# HC32K118 register map
File version: 1.0
CPU: CM0+ r0p1, little endian, no MPU, no FPU, 2 interrupt priority bits
Registers are 32-bit, read-write, reset 0x0 unless marked. A register's access mark holds for its fields unless they carry their own. Offsets are from the block's base; [hi:lo] are bit positions; {n}, {i} and the like mark numbered series; 'fields as' and 'values as' point back to an identical list.

## DMA
Base 0x40013000
0x00 EN
  [0] EN
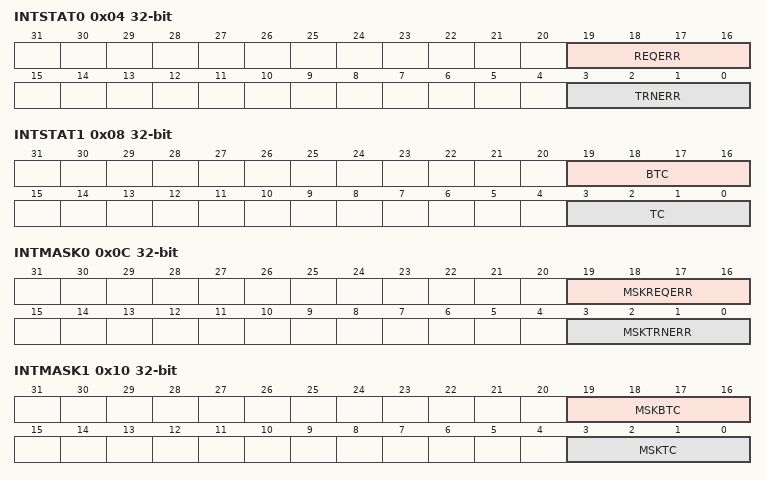
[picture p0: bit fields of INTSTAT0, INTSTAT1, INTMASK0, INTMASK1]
0x04 INTSTAT0 ro
  [19:16] REQERR, [3:0] TRNERR
0x08 INTSTAT1 ro
  [19:16] BTC, [3:0] TC
0x0C INTMASK0
  [19:16] MSKREQERR, [3:0] MSKTRNERR
0x10 INTMASK1
  [19:16] MSKBTC, [3:0] MSKTC
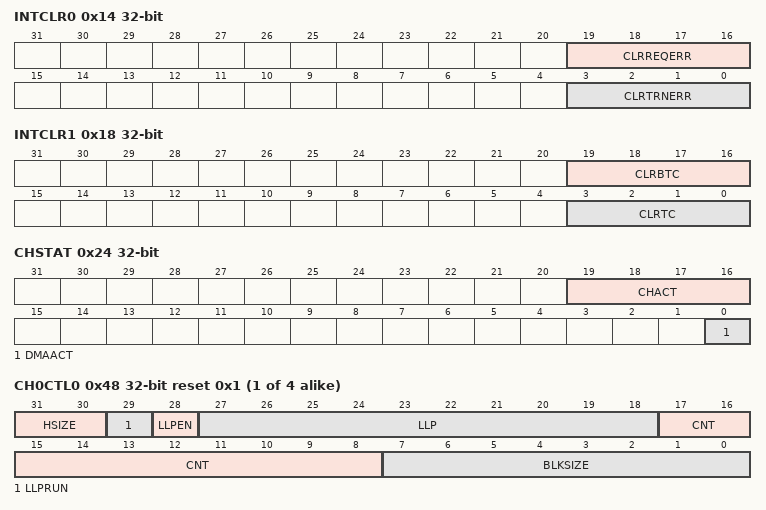
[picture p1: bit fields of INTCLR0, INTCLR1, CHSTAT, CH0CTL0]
0x14 INTCLR0 wo
  [19:16] CLRREQERR, [3:0] CLRTRNERR
0x18 INTCLR1 wo
  [19:16] CLRBTC, [3:0] CLRTC
0x1C CHEN
  [3:0] CHEN
0x24 CHSTAT ro
  [19:16] CHACT, [0] DMAACT
0x30 BASE1_LLP reset 0x20000000
  [31:14] LLP
0x34 BASE2_LLP
  [31:14] LLP
0x38 CHENCLR wo
  [3:0] CHENCLR
{0x40+0x40*i} SAR{i} (i=0..3)
{0x44+0x40*i} DAR{i} (i=0..3)
{0x48+0x40*i} CH{i}CTL0 reset 0x1 (i=0..3)
  [31:30] HSIZE, [29] LLPRUN, [28] LLPEN, [27:18] LLP, [17:8] CNT, [7:0] BLKSIZE
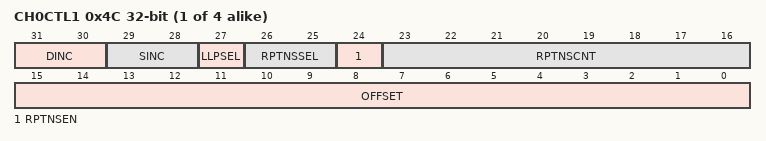
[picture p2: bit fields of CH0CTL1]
{0x4C+0x40*i} CH{i}CTL1 (i=0..3)
  [31:30] DINC, [29:28] SINC, [27] LLPSEL, [26:25] RPTNSSEL, [24] RPTNSEN, [23:16] RPTNSCNT, [15:0] OFFSET

## EFM
Base 0x40000400
0x00 DFAPRT
  [15:0] FAPRT
0x04 DKEY1
0x08 DKEY2
0x14 DFSTP
  [0] FSTP
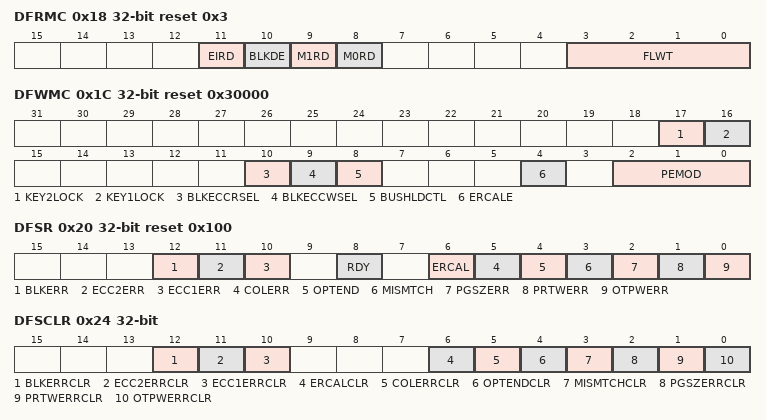
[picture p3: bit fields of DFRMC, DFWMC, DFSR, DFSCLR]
0x18 DFRMC reset 0x3
  [11] EIRD, [10] BLKDE, [9] M1RD, [8] M0RD, [3:0] FLWT
0x1C DFWMC reset 0x30000
  [17] KEY2LOCK, [16] KEY1LOCK, [10] BLKECCRSEL, [9] BLKECCWSEL, [8] BUSHLDCTL, [4] ERCALE, [2:0] PEMOD
0x20 DFSR ro reset 0x100
  [12] BLKERR, [11] ECC2ERR, [10] ECC1ERR, [8] RDY, [6] ERCAL, [5] COLERR, [4] OPTEND, [3] MISMTCH, [2] PGSZERR, [1] PRTWERR, [0] OTPWERR
0x24 DFSCLR
  [12] BLKERRCLR, [11] ECC2ERRCLR, [10] ECC1ERRCLR, [6] ERCALCLR, [5] COLERRCLR, [4] OPTENDCLR, [3] MISMTCHCLR, [2] PGSZERRCLR, [1] PRTWERRCLR, [0] OTPWERRCLR
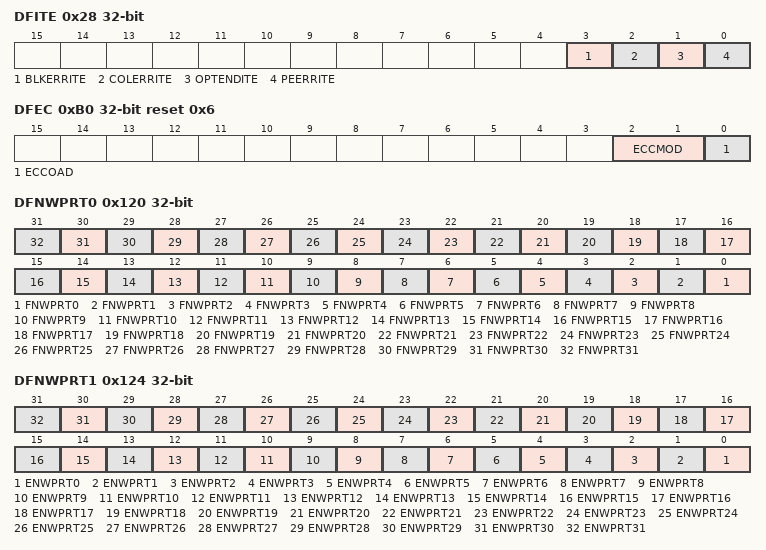
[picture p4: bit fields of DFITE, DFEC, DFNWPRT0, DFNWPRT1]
0x28 DFITE
  [3] BLKERRITE, [2] COLERRITE, [1] OPTENDITE, [0] PEERRITE
0xB0 DFEC reset 0x6
  [2:1] ECCMOD, [0] ECCOAD
0xB4 DFECERA ro reset 0x40000000
0xB8 DERI0
0xC0 DERI2
  [6:0] ERI2
0x120 DFNWPRT0
  [n] FNWPRT{n} (n=0..31)
0x124 DFNWPRT1
  [n] ENWPRT{n} (n=0..31)
0x400 FAPRT
  [15:0] FAPRT
0x404 KEY1
0x408 KEY2
0x414 FSTP
  [0] FSTP
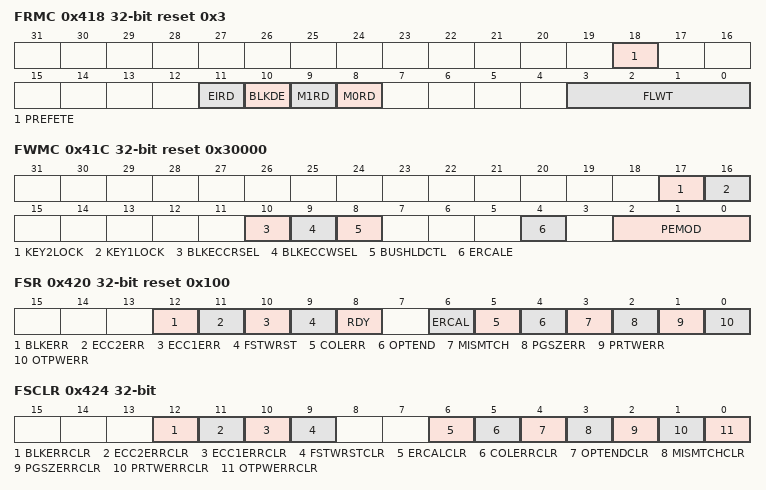
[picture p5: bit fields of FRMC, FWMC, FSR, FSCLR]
0x418 FRMC reset 0x3
  [18] PREFETE, [11] EIRD, [10] BLKDE, [9] M1RD, [8] M0RD, [3:0] FLWT
0x41C FWMC reset 0x30000
  fields as DFWMC
0x420 FSR ro reset 0x100
  [12] BLKERR, [11] ECC2ERR, [10] ECC1ERR, [9] FSTWRST, [8] RDY, [6] ERCAL, [5] COLERR, [4] OPTEND, [3] MISMTCH, [2] PGSZERR, [1] PRTWERR, [0] OTPWERR
0x424 FSCLR
  [12] BLKERRCLR, [11] ECC2ERRCLR, [10] ECC1ERRCLR, [9] FSTWRSTCLR, [6] ERCALCLR, [5] COLERRCLR, [4] OPTENDCLR, [3] MISMTCHCLR, [2] PGSZERRCLR, [1] PRTWERRCLR, [0] OTPWERRCLR
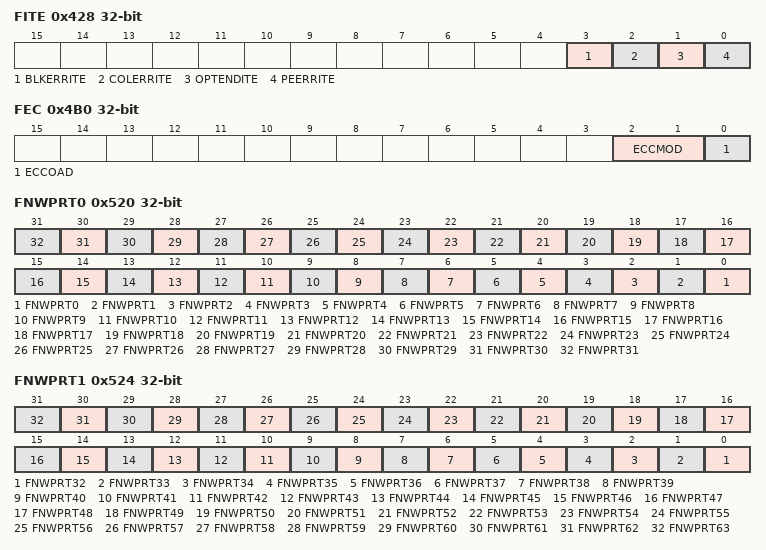
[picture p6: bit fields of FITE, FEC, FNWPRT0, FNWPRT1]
0x428 FITE
  [3] BLKERRITE, [2] COLERRITE, [1] OPTENDITE, [0] PEERRITE
0x42C FSWP ro
  [0] FSWP
0x440 CHIPID ro reset 0x58480118
{0x450+4i} UQID{i} ro (i=0..2)
0x4B0 FEC
  [2:1] ECCMOD, [0] ECCOAD
0x4B4 FECERA ro
0x4B8 ERI0
0x4BC ERI1
0x4C0 ERI2
  [7:0] ERI2
0x520 FNWPRT0
  [n] FNWPRT{n} (n=0..31)
0x524 FNWPRT1
  [n-32] FNWPRT{n} (n=32..63)
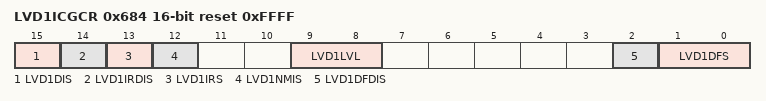
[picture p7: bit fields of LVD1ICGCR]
0x684 LVD1ICGCR 16-bit ro reset 0xFFFF
  [15] LVD1DIS, [14] LVD1IRDIS, [13] LVD1IRS, [12] LVD1NMIS, [9:8] LVD1LVL, [2] LVD1DFDIS, [1:0] LVD1DFS
0x686 HRCCFGR 8-bit
  [3:0] HRCFREQS

## EMB
Base 0x40006C00
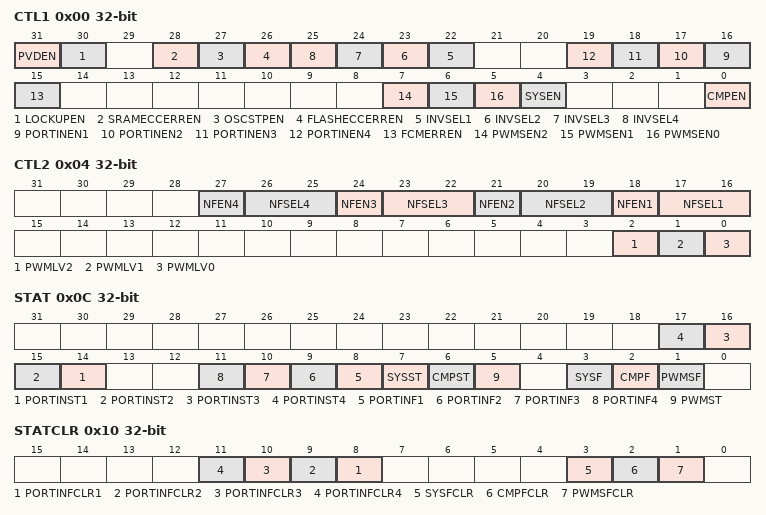
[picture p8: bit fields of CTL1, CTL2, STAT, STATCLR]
0x00 CTL1
  [31] PVDEN, [30] LOCKUPEN, [28] SRAMECCERREN, [27] OSCSTPEN, [26] FLASHECCERREN, [n+21] INVSEL{n} (n=1..4), [n+15] PORTINEN{n} (n=1..4), [15] FCMERREN, [7] PWMSEN2, [6] PWMSEN1, [5] PWMSEN0, [4] SYSEN, [0] CMPEN
0x04 CTL2
  [3n+15] NFEN{n} (n=1..4), [3n+14:3n+13] NFSEL{n} (n=1..4), [2] PWMLV2, [1] PWMLV1, [0] PWMLV0
0x08 SOE
  [0] SOE
0x0C STAT ro
  [n+13] PORTINST{n} (n=1..4), [n+7] PORTINF{n} (n=1..4), [7] SYSST, [6] CMPST, [5] PWMST, [3] SYSF, [2] CMPF, [1] PWMSF
0x10 STATCLR wo
  [n+7] PORTINFCLR{n} (n=1..4), [3] SYSFCLR, [2] CMPFCLR, [1] PWMSFCLR
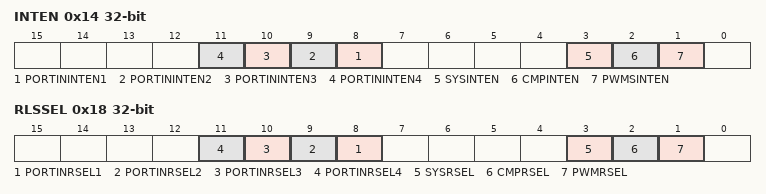
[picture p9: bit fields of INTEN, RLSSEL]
0x14 INTEN
  [n+7] PORTININTEN{n} (n=1..4), [3] SYSINTEN, [2] CMPINTEN, [1] PWMSINTEN
0x18 RLSSEL
  [n+7] PORTINRSEL{n} (n=1..4), [3] SYSRSEL, [2] CMPRSEL, [1] PWMRSEL

## FCM
Base 0x40005400
0x00 LVR
  [15:0] LVR
0x04 UVR
  [15:0] UVR
0x08 CNTR ro
  [15:0] CNTR
0x0C STR
  [0] START
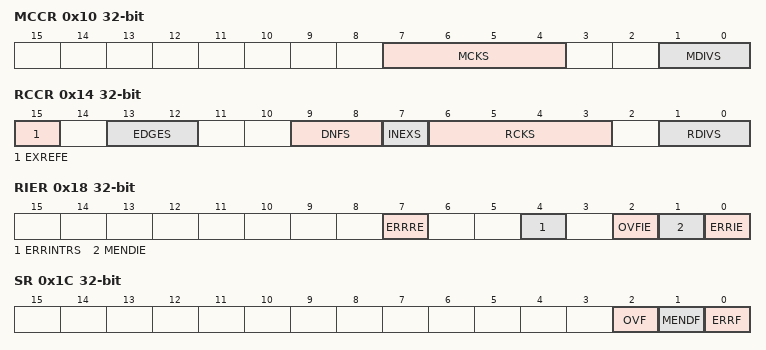
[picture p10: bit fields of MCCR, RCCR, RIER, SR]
0x10 MCCR
  [7:4] MCKS, [1:0] MDIVS
0x14 RCCR
  [15] EXREFE, [13:12] EDGES, [9:8] DNFS, [7] INEXS, [6:3] RCKS, [1:0] RDIVS
0x18 RIER
  [7] ERRRE, [4] ERRINTRS, [2] OVFIE, [1] MENDIE, [0] ERRIE
0x1C SR ro
  [2] OVF, [1] MENDF, [0] ERRF
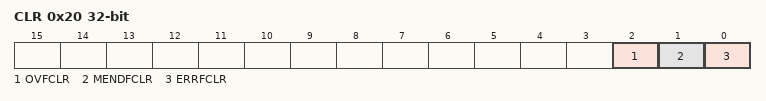
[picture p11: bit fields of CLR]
0x20 CLR wo
  [2] OVFCLR, [1] MENDFCLR, [0] ERRFCLR
